# G32F031 register map
File version: 1.0
CPU: CM0PLUS r0p1, little endian, no MPU, no FPU, 2 interrupt priority bits
Registers are 32-bit, read-write, reset 0x0 unless marked. A register's access mark holds for its fields unless they carry their own. Offsets are from the block's base; [hi:lo] are bit positions; {n}, {i} and the like mark numbered series; 'fields as' and 'values as' point back to an identical list.

## COMP0 — Comparator
Base 0x40005C00
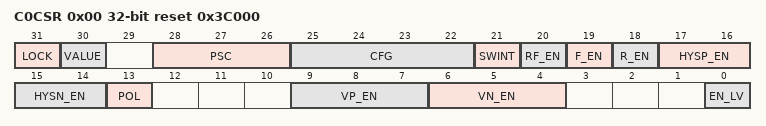
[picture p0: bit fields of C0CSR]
0x00 C0CSR access per field reset 0x3C000 — Control Register 0
  [31] LOCK rw
  [30] VALUE ro — Comparator outputs the level value before polarity selector and shielding.
  [28:26] PSC rw — Digital filter fractional division configuration
  [25:22] CFG rw — Digital filter fractional clock configuration
  [21] SWINT rw — soft interrupt
  [20] RF_EN rw — Comparator interrupt rising and falling edge enable
  [19] F_EN rw — Comparator interrupt falling edge enable
  [18] R_EN rw — Comparator interrupt rising edge enable
  [17:16] HYSP_EN rw — Delay function enabled
  [15:14] HYSN_EN rw — Delay function enabled
  [13] POL rw — The output polarity of comparator .
  [9:7] VP_EN rw — Comparator positive input voltage selection
  [6:4] VN_EN rw — Comparator negative input voltage selection
  [0] EN_LV rw — Module enablement
0x04 PEND0 — Status register 0
  [0] PEND — interrupt flag

## COMP1 — Comparator
Base 0x40006000
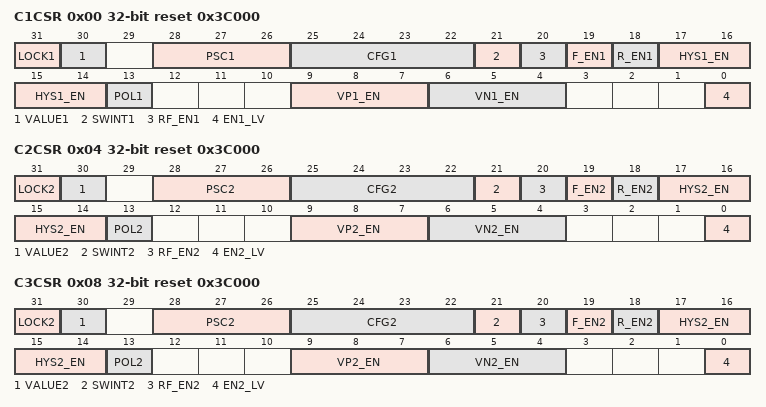
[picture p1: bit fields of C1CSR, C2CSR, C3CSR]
0x00 C1CSR access per field reset 0x3C000 — Control Register 1
  [31] LOCK1 rw — lock
  [30] VALUE1 ro — Comparator outputs the level value before polarity selector and shielding.
  [28:26] PSC1 rw — Digital filter fractional division configuration
  [25:22] CFG1 rw — Digital filter fractional clock configuration
  [21] SWINT1 rw — soft interrupt
  [20] RF_EN1 rw — Comparator interrupt rising and falling edge enable
  [19] F_EN1 rw — Comparator interrupt falling edge enable
  [18] R_EN1 rw — Comparator interrupt rising edge enable
  [17:14] HYS1_EN rw — Delay function enabled
  [13] POL1 rw — The output polarity of comparator .
  [9:7] VP1_EN rw — Comparator positive input voltage selection
  [6:4] VN1_EN rw — Comparator negative input voltage selection
  [0] EN1_LV rw — Module enablement
0x04 C2CSR access per field reset 0x3C000 — Control Register 2
  [31] LOCK2 rw — lock
  [30] VALUE2 ro — Comparator outputs the level value before polarity selector and shielding.
  [28:26] PSC2 rw — Digital filter fractional division configuration
  [25:22] CFG2 rw — Digital filter fractional clock configuration
  [21] SWINT2 rw — soft interrupt
  [20] RF_EN2 rw — Comparator interrupt rising and falling edge enable
  [19] F_EN2 rw — Comparator interrupt falling edge enable
  [18] R_EN2 rw — Comparator interrupt rising edge enable
  [17:14] HYS2_EN rw — Delay function enabled
  [13] POL2 rw — The output polarity of comparator .
  [9:7] VP2_EN rw — Comparator positive input voltage selection
  [6:4] VN2_EN rw — Comparator negative input voltage selection
  [0] EN2_LV rw — Module enablement
0x08 C3CSR access per field reset 0x3C000 — Control Register 3
  fields as C2CSR
{0x0+4i} PEND{i} (i=3..5) — Status register 1
  [0] PEND{i} — interrupt flag

## DMA — DMA controller
Base 0x40020000
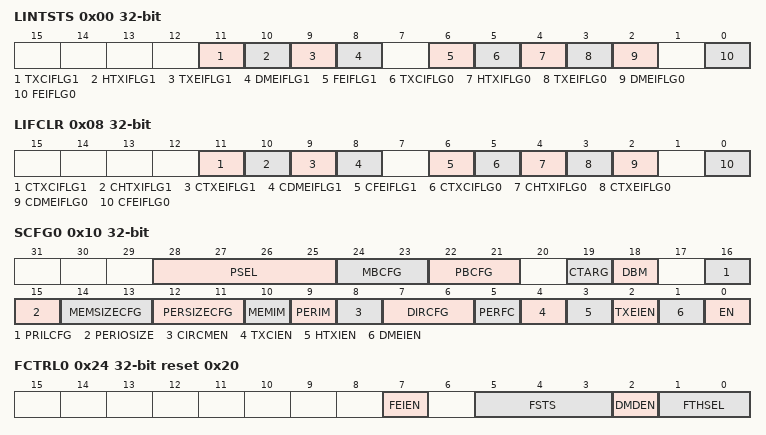
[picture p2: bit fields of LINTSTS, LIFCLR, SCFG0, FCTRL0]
0x00 LINTSTS ro
  [11] TXCIFLG1 — Stream 1 transfer complete interrupt flag
  [10] HTXIFLG1 — Stream 1 half transfer interrupt flag
  [9] TXEIFLG1 — Stream 1 transfer error interrupt flag
  [8] DMEIFLG1 — Stream 1 direct mode error interrupt flag
  [6] FEIFLG1 — Stream 1 FIFO error interrupt flag
  [5] TXCIFLG0 — Stream 0 transfer complete interrupt flag
  [4] HTXIFLG0 — Stream 0 half transfer interrupt flag
  [3] TXEIFLG0 — Stream 0 transfer error interrupt flag
  [2] DMEIFLG0 — Stream 0 direct mode error interrupt flag
  [0] FEIFLG0 — Stream 0 FIFO error interrupt flag
0x08 LIFCLR
  [11] CTXCIFLG1 — Stream 1 clear transfer complete interrupt flag
  [10] CHTXIFLG1 — Stream 1 clear half transfer interrupt flag
  [9] CTXEIFLG1 — Stream 1 clear transfer error interrupt flag
  [8] CDMEIFLG1 — Stream 1 clear direct mode error interrupt flag
  [6] CFEIFLG1 — Stream 1 clear FIFO error interrupt flag
  [5] CTXCIFLG0 — Stream 0 clear transfer complete interrupt flag
  [4] CHTXIFLG0 — Stream 0 clear half transfer interrupt flag
  [3] CTXEIFLG0 — Stream 0 clear transfer error interrupt flag
  [2] CDMEIFLG0 — Stream 0 clear direct mode error interrupt flag
  [0] CFEIFLG0 — Stream 0 clear FIFO error interrupt flag
0x10 SCFG0
  [28:25] PSEL — Channel selection
  [24:23] MBCFG — Memory burst transfer configuration
  [22:21] PBCFG — Peripheral burst transfer configuration
  [19] CTARG — Current target (only in double buffer mode)
  [18] DBM — Double buffer mode
  [16] PRILCFG — Priority level
  [15] PERIOSIZE — Peripheral increment offset size
  [14:13] MEMSIZECFG — Memory data size
  [12:11] PERSIZECFG — Peripheral data size
  [10] MEMIM — Memory increment mode
  [9] PERIM — Peripheral increment mode
  [8] CIRCMEN — Circular mode
  [7:6] DIRCFG — Data transfer direction
  [5] PERFC — Peripheral flow controller
  [4] TXCIEN — Transfer complete interrupt enable
  [3] HTXIEN — Half transfer interrupt enable
  [2] TXEIEN — Transfer error interrupt enable
  [1] DMEIEN — Direct mode error interrupt enable
  [0] EN — Stream enable / flag stream ready when read low
0x14 NDATA0
  [15:0] NDATA — Number of data items to transfer
0x18 PADDR0
  [31:0] PADDR — Peripheral address
0x1C M0ADDR0
  [31:0] M0ADDR — Memory 0 address
0x20 M1ADDR0
  [31:0] M1ADDR — Memory 1 address (used in case of Double buffer mode)
0x24 FCTRL0 access per field reset 0x20
  [7] FEIEN rw — FIFO error interrupt enable
  [5:3] FSTS ro — FIFO status
  [2] DMDEN rw — Direct mode disable
  [1:0] FTHSEL rw — FIFO threshold selection
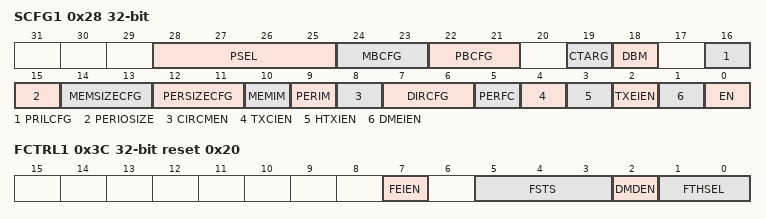
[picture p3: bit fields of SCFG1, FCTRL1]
0x28 SCFG1
  fields as SCFG0
0x2C NDATA1
  [15:0] NDATA — Number of data items to transfer
0x30 PADDR1
  [31:0] PADDR — Peripheral address
0x34 M0ADDR1 reset 0xFFF0000
  [31:0] M0ADDR — Memory 0 address
0x38 M1ADDR1
  fields as M1ADDR0
0x3C FCTRL1 access per field reset 0x20
  fields as FCTRL0
